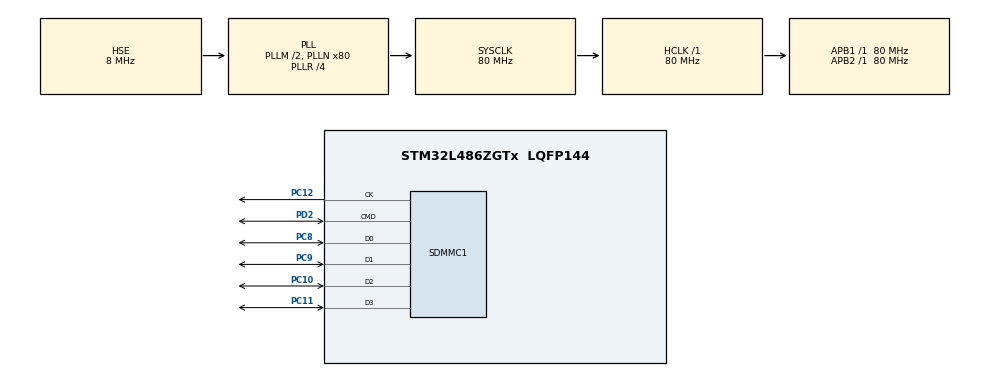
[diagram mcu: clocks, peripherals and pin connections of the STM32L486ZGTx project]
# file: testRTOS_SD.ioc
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Dma.Request0=SDMMC1
Dma.SDMMC1.0.Direction=DMA_PERIPH_TO_MEMORY
Dma.SDMMC1.0.Instance=DMA2_Channel4
Dma.SDMMC1.0.MemDataAlignment=DMA_MDATAALIGN_WORD
Dma.SDMMC1.0.MemInc=DMA_MINC_ENABLE
Dma.SDMMC1.0.Mode=DMA_NORMAL
Dma.SDMMC1.0.PeriphDataAlignment=DMA_PDATAALIGN_WORD
Dma.SDMMC1.0.PeriphInc=DMA_PINC_DISABLE
Dma.SDMMC1.0.Priority=DMA_PRIORITY_LOW
FATFS._FS_LOCK=10
FATFS._FS_REENTRANT=0
FATFS._MAX_SS=4096
FREERTOS.Tasks01=defaultTask,24,128,StartDefaultTask,Default,NULL,Dynamic,NULL,NULL
Mcu.Family=STM32L4
Mcu.Name=STM32L486ZGTx
Mcu.Package=LQFP144
NVIC.DMA2_Channel4_IRQn=true\:5\:0\:false\:false\:true\:true\:false\:true\:true
NVIC.PriorityGroup=NVIC_PRIORITYGROUP_4
NVIC.SDMMC1_IRQn=true\:5\:0\:false\:false\:true\:true\:true\:true\:true
NVIC.TIM6_DAC_IRQn=true\:15\:0\:false\:false\:true\:false\:false\:true\:true
NVIC.TimeBase=TIM6_DAC_IRQn
NVIC.TimeBaseIP=TIM6
PC10.GPIO_PuPd=GPIO_PULLUP
PC10.Mode=SD_4_bits_Wide_bus
PC10.Signal=SDMMC1_D2
PC11.GPIO_PuPd=GPIO_PULLUP
PC11.Mode=SD_4_bits_Wide_bus
PC11.Signal=SDMMC1_D3
PC12.Mode=SD_4_bits_Wide_bus
PC12.Signal=SDMMC1_CK
PC14-OSC32_IN\ (PC14).Mode=LSE-External-Oscillator
PC14-OSC32_IN\ (PC14).Signal=RCC_OSC32_IN
PC15-OSC32_OUT\ (PC15).Mode=LSE-External-Oscillator
PC15-OSC32_OUT\ (PC15).Signal=RCC_OSC32_OUT
PC8.GPIO_PuPd=GPIO_PULLUP
PC8.Mode=SD_4_bits_Wide_bus
PC8.Signal=SDMMC1_D0
PC9.GPIO_PuPd=GPIO_PULLUP
PC9.Mode=SD_4_bits_Wide_bus
PC9.Signal=SDMMC1_D1
PD2.GPIO_PuPd=GPIO_PULLUP
PD2.Mode=SD_4_bits_Wide_bus
PD2.Signal=SDMMC1_CMD
PH0-OSC_IN\ (PH0).Mode=HSE-External-Oscillator
PH0-OSC_IN\ (PH0).Signal=RCC_OSC_IN
PH1-OSC_OUT\ (PH1).Mode=HSE-External-Oscillator
PH1-OSC_OUT\ (PH1).Signal=RCC_OSC_OUT
ProjectManager.HeapSize=0x200
ProjectManager.StackSize=0x400
ProjectManager.TargetToolchain=STM32CubeIDE
RCC.ADCFreq_Value=48000000
RCC.AHBFreq_Value=80000000
RCC.APB1Freq_Value=80000000
RCC.APB1TimFreq_Value=80000000
RCC.APB2Freq_Value=80000000
RCC.APB2TimFreq_Value=80000000
RCC.CortexFreq_Value=80000000
RCC.HCLKFreq_Value=80000000
RCC.HSE_VALUE=8000000
RCC.HSI_VALUE=16000000
RCC.MSI_VALUE=4000000
RCC.PLLM=2
RCC.PLLN=80
RCC.PLLR=RCC_PLLR_DIV4
RCC.PLLSAI1N=24
RCC.PLLSourceVirtual=RCC_PLLSOURCE_HSE
RCC.SYSCLKFreq_VALUE=80000000
RCC.SYSCLKSource=RCC_SYSCLKSOURCE_PLLCLK
RCC.USBFreq_Value=48000000
RCC.VCOOutputFreq_Value=320000000
SDMMC1.ClockDiv=46
VP_FATFS_VS_SDIO.Mode=SDIO
VP_FREERTOS_VS_CMSIS_V2.Mode=CMSIS_V2
VP_SYS_VS_tim6.Mode=TIM6
board=custom

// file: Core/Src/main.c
/**
  ******************************************************************************
  * @file           : main.c
  * @brief          : Main program body
  ******************************************************************************
  * @attention
  *
  * Copyright (c) 2023 STMicroelectronics.
  * All rights reserved.
  *
  * This software is licensed under terms that can be found in the LICENSE file
  * in the root directory of this software component.
  * If no LICENSE file comes with this software, it is provided AS-IS.
  *
  ******************************************************************************
  */
/* USER CODE END Header */
#include "main.h"
#include "cmsis_os.h"
#include "fatfs.h"

SD_HandleTypeDef hsd1;
DMA_HandleTypeDef hdma_sdmmc1;

/* Definitions for defaultTask */
osThreadId_t defaultTaskHandle;
const osThreadAttr_t defaultTask_attributes = {
  .name = "defaultTask",
  .stack_size = 128 * 4,
  .priority = (osPriority_t) osPriorityNormal,
};

void SystemClock_Config(void);
static void MX_GPIO_Init(void);
static void MX_DMA_Init(void);
static void MX_SDMMC1_SD_Init(void);
void StartDefaultTask(void *argument);

/* USER CODE BEGIN 0 */
//SD Card Variables FATFS
extern char SDPath[4];   /* SD logical drive path */
extern FATFS SDFatFS;    /* File system object for SD logical drive */
extern FIL SDFile;       /* File object for SD */
//FILE I/O Variables
FRESULT res;                                          /* FatFs function common result code */
uint32_t byteswritten, bytesread;                     /* File write/read counts */
uint8_t wtext[] = "Hello from Mohamed :), SDIO DMA RTOS"; /* File write buffer */
uint8_t rtext[100];                                   /* File read buffer */

/* USER CODE END 0 */

int main(void)
{

  /* MCU Configuration--------------------------------------------------------*/

  /* Reset of all peripherals, Initializes the Flash interface and the Systick. */
  HAL_Init();

  /* Configure the system clock */
  SystemClock_Config();

  /* Initialize all configured peripherals */
  MX_GPIO_Init();
  MX_DMA_Init();
  MX_SDMMC1_SD_Init();
  MX_FATFS_Init();

  /* Init scheduler */
  osKernelInitialize();

  /* Create the thread(s) */
  /* creation of defaultTask */
  defaultTaskHandle = osThreadNew(StartDefaultTask, NULL, &defaultTask_attributes);

  /* Start scheduler */
  osKernelStart();

  /* We should never get here as control is now taken by the scheduler */
  /* Infinite loop */
  while (1)
  {

  }
}

void SystemClock_Config(void)
{
  RCC_OscInitTypeDef RCC_OscInitStruct = {0};
  RCC_ClkInitTypeDef RCC_ClkInitStruct = {0};

  /** Configure the main internal regulator output voltage
  */
  if (HAL_PWREx_ControlVoltageScaling(PWR_REGULATOR_VOLTAGE_SCALE1) != HAL_OK)
  {
    Error_Handler();
  }

  /** Initializes the RCC Oscillators according to the specified parameters
  * in the RCC_OscInitTypeDef structure.
  */
  RCC_OscInitStruct.OscillatorType = RCC_OSCILLATORTYPE_HSE;
  RCC_OscInitStruct.HSEState = RCC_HSE_ON;
  RCC_OscInitStruct.PLL.PLLState = RCC_PLL_ON;
  RCC_OscInitStruct.PLL.PLLSource = RCC_PLLSOURCE_HSE;
  RCC_OscInitStruct.PLL.PLLM = 2;
  RCC_OscInitStruct.PLL.PLLN = 80;
  RCC_OscInitStruct.PLL.PLLP = RCC_PLLP_DIV7;
  RCC_OscInitStruct.PLL.PLLQ = RCC_PLLQ_DIV2;
  RCC_OscInitStruct.PLL.PLLR = RCC_PLLR_DIV4;
  if (HAL_RCC_OscConfig(&RCC_OscInitStruct) != HAL_OK)
  {
    Error_Handler();
  }

  /** Initializes the CPU, AHB and APB buses clocks
  */
  RCC_ClkInitStruct.ClockType = RCC_CLOCKTYPE_HCLK|RCC_CLOCKTYPE_SYSCLK
                              |RCC_CLOCKTYPE_PCLK1|RCC_CLOCKTYPE_PCLK2;
  RCC_ClkInitStruct.SYSCLKSource = RCC_SYSCLKSOURCE_PLLCLK;
  RCC_ClkInitStruct.AHBCLKDivider = RCC_SYSCLK_DIV1;
  RCC_ClkInitStruct.APB1CLKDivider = RCC_HCLK_DIV1;
  RCC_ClkInitStruct.APB2CLKDivider = RCC_HCLK_DIV1;

  if (HAL_RCC_ClockConfig(&RCC_ClkInitStruct, FLASH_LATENCY_4) != HAL_OK)
  {
    Error_Handler();
  }
}

static void MX_SDMMC1_SD_Init(void)
{

  hsd1.Instance = SDMMC1;
  hsd1.Init.ClockEdge = SDMMC_CLOCK_EDGE_RISING;
  hsd1.Init.ClockBypass = SDMMC_CLOCK_BYPASS_DISABLE;
  hsd1.Init.ClockPowerSave = SDMMC_CLOCK_POWER_SAVE_DISABLE;
  hsd1.Init.BusWide = SDMMC_BUS_WIDE_1B;
  hsd1.Init.HardwareFlowControl = SDMMC_HARDWARE_FLOW_CONTROL_DISABLE;
  hsd1.Init.ClockDiv = 46;

}

static void MX_DMA_Init(void)
{

  /* DMA controller clock enable */
  __HAL_RCC_DMA2_CLK_ENABLE();

  /* DMA interrupt init */
  /* DMA2_Channel4_IRQn interrupt configuration */
  HAL_NVIC_SetPriority(DMA2_Channel4_IRQn, 5, 0);
  HAL_NVIC_EnableIRQ(DMA2_Channel4_IRQn);

}

static void MX_GPIO_Init(void)
{

  /* GPIO Ports Clock Enable */
  __HAL_RCC_GPIOC_CLK_ENABLE();
  __HAL_RCC_GPIOH_CLK_ENABLE();
  __HAL_RCC_GPIOD_CLK_ENABLE();

}

void StartDefaultTask(void *argument)
{
  /* USER CODE BEGIN 5 */
	 MX_FATFS_Init();

	  /* USER CODE BEGIN 5 */
		//1. Mount - 0
		f_mount(&SDFatFS, (TCHAR const*)SDPath, 0);

		//TEST Write operation
		//2. Open file for Writing
		if(f_open(&SDFile, "F7FILE1.TXT", FA_OPEN_APPEND | FA_WRITE) != FR_OK)
		{
			while(1);
		}
		else
		{
		}
		f_close(&SDFile);
		while(1);

  /* Infinite loop */
  for(;;)
  {
    osDelay(1);
  }
  /* USER CODE END 5 */
}

void HAL_TIM_PeriodElapsedCallback(TIM_HandleTypeDef *htim)
{
  if (htim->Instance == TIM6) {
    HAL_IncTick();
  }
}

void Error_Handler(void)
{
  __disable_irq();
  while (1)
  {
  }
}
